# WKUP_ECC_AGGR0_ECC_AGGR register map
Vendor: Texas Instruments
Peripheral module from a debugger description file (folder am65x).
Registers are 32-bit, access not given, reset 0x0 unless marked. A register's access mark holds for its fields unless they carry their own. Offsets are as the file gives them; lines under a group give offsets from that group; [hi:lo] are bit positions; {n}, {i} and the like mark numbered series; 'fields as' and 'values as' point back to an identical list; <NAME> marks a mode.

## WKUP_ECC_AGGR0_ECC_AGGR
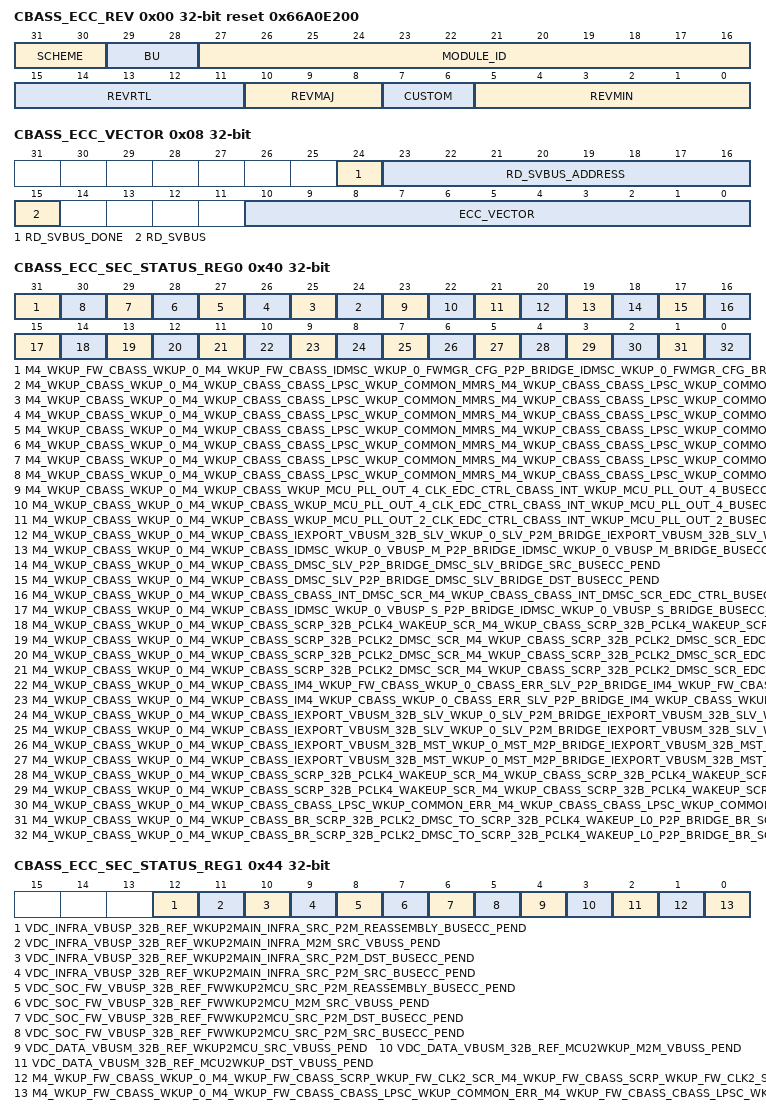
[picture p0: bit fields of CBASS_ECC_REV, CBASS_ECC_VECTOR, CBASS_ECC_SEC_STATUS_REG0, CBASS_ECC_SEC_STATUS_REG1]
0x00 CBASS_ECC_REV ro reset 0x66A0E200 — Return to the . Revision parameters
  [31:30] SCHEME
  [29:28] BU
  [27:16] MODULE_ID
  [15:11] REVRTL — RTL version
  [10:8] REVMAJ — Major version
  [7:6] CUSTOM — Custom version
  [5:0] REVMIN — Minor version
0x08 CBASS_ECC_VECTOR — Return to the . ECC Vector Register
  [24] RD_SVBUS_DONE — Status to indicate if read on serial VBUS is complete, write of any value will clear this bit. (access RW1C)
  [23:16] RD_SVBUS_ADDRESS rw — Read address
  [15] RD_SVBUS — Write 1 to trigger a read on the serial VBUS (access RW1S)
  [10:0] ECC_VECTOR rw — Value written to select the corresponding ECC RAM for control or status
0x0C CBASS_ECC_STAT ro reset 0x2D — Return to the . Misc Status
  [10:0] NUM_RAMS — Indicates the number of RAMS serviced by the ECC aggregator
0x3C CBASS_ECC_SEC_EOI_REG — Return to the . EOI Register
  [0] EOI_WR — EOI Register (access RW1S)
0x40 CBASS_ECC_SEC_STATUS_REG0 — Return to the . Interrupt Status Register 0
  [31] M4_WKUP_FW_CBASS_WKUP_0_M4_WKUP_FW_CBASS_IDMSC_WKUP_0_FWMGR_CFG_P2P_BRIDGE_IDMSC_WKUP_0_FWMGR_CFG_BRIDGE_BUSECC_PEND — Interrupt Pending Status for m4_wkup_fw_cbass_wkup_0_m4_wkup_fw_cbass_Idmsc_wkup_0_fwmgr_cfg_p2p_bridge_Idmsc_wkup_0_fwmgr_cfg_bridge_busecc__pend (access RW1S)
  [n+24] M4_WKUP_CBASS_WKUP_0_M4_WKUP_CBASS_CBASS_LPSC_WKUP_COMMON_MMRS_M4_WKUP_CBASS_CBASS_LPSC_WKUP_COMMON_MMRS_EDC_CTRL_BUSECC_{n}_PEND (n=0..6) — Interrupt Pending Status for m4_wkup_cbass_wkup_0_m4_wkup_cbass_cbass_LPSC_wkup_common_mmrs_m4_wkup_cbass_cbass_LPSC_wkup_common_mmrs_edc_ctrl_busecc_{n}__pend (access RW1S)
  [23] M4_WKUP_CBASS_WKUP_0_M4_WKUP_CBASS_WKUP_MCU_PLL_OUT_4_CLK_EDC_CTRL_CBASS_INT_WKUP_MCU_PLL_OUT_4_BUSECC_1_PEND — Interrupt Pending Status for m4_wkup_cbass_wkup_0_m4_wkup_cbass_wkup_mcu_pll_out_4_clk_edc_ctrl_cbass_int_wkup_mcu_pll_out_4_busecc_1__pend (access RW1S)
  [22] M4_WKUP_CBASS_WKUP_0_M4_WKUP_CBASS_WKUP_MCU_PLL_OUT_4_CLK_EDC_CTRL_CBASS_INT_WKUP_MCU_PLL_OUT_4_BUSECC_0_PEND — Interrupt Pending Status for m4_wkup_cbass_wkup_0_m4_wkup_cbass_wkup_mcu_pll_out_4_clk_edc_ctrl_cbass_int_wkup_mcu_pll_out_4_busecc_0__pend (access RW1S)
  [21] M4_WKUP_CBASS_WKUP_0_M4_WKUP_CBASS_WKUP_MCU_PLL_OUT_2_CLK_EDC_CTRL_CBASS_INT_WKUP_MCU_PLL_OUT_2_BUSECC_PEND — Interrupt Pending Status for m4_wkup_cbass_wkup_0_m4_wkup_cbass_wkup_mcu_pll_out_2_clk_edc_ctrl_cbass_int_wkup_mcu_pll_out_2_busecc__pend (access RW1S)
  [20] M4_WKUP_CBASS_WKUP_0_M4_WKUP_CBASS_IEXPORT_VBUSM_32B_SLV_WKUP_0_SLV_P2M_BRIDGE_IEXPORT_VBUSM_32B_SLV_WKUP_0_SLV_BRIDGE_REASSEMBLY_BUSECC_PEND — Interrupt Pending Status for m4_wkup_cbass_wkup_0_m4_wkup_cbass_Iexport_vbusm_32b_slv_wkup_0_slv_p2m_bridge_Iexport_vbusm_32b_slv_wkup_0_slv_bridge_reassembly_busecc__pend (access RW1S)
  [19] M4_WKUP_CBASS_WKUP_0_M4_WKUP_CBASS_IDMSC_WKUP_0_VBUSP_M_P2P_BRIDGE_IDMSC_WKUP_0_VBUSP_M_BRIDGE_BUSECC_PEND — Interrupt Pending Status for m4_wkup_cbass_wkup_0_m4_wkup_cbass_Idmsc_wkup_0_vbusp_m_p2p_bridge_Idmsc_wkup_0_vbusp_m_bridge_busecc__pend (access RW1S)
  [18] M4_WKUP_CBASS_WKUP_0_M4_WKUP_CBASS_DMSC_SLV_P2P_BRIDGE_DMSC_SLV_BRIDGE_SRC_BUSECC_PEND — Interrupt Pending Status for m4_wkup_cbass_wkup_0_m4_wkup_cbass_dmsc_slv_p2p_bridge_dmsc_slv_bridge_src_busecc__pend (access RW1S)
  [17] M4_WKUP_CBASS_WKUP_0_M4_WKUP_CBASS_DMSC_SLV_P2P_BRIDGE_DMSC_SLV_BRIDGE_DST_BUSECC_PEND — Interrupt Pending Status for m4_wkup_cbass_wkup_0_m4_wkup_cbass_dmsc_slv_p2p_bridge_dmsc_slv_bridge_dst_busecc__pend (access RW1S)
  [16] M4_WKUP_CBASS_WKUP_0_M4_WKUP_CBASS_CBASS_INT_DMSC_SCR_M4_WKUP_CBASS_CBASS_INT_DMSC_SCR_EDC_CTRL_BUSECC_PEND — Interrupt Pending Status for m4_wkup_cbass_wkup_0_m4_wkup_cbass_cbass_int_dmsc_scr_m4_wkup_cbass_cbass_int_dmsc_scr_edc_ctrl_busecc__pend (access RW1S)
  [15] M4_WKUP_CBASS_WKUP_0_M4_WKUP_CBASS_IDMSC_WKUP_0_VBUSP_S_P2P_BRIDGE_IDMSC_WKUP_0_VBUSP_S_BRIDGE_BUSECC_PEND — Interrupt Pending Status for m4_wkup_cbass_wkup_0_m4_wkup_cbass_Idmsc_wkup_0_vbusp_s_p2p_bridge_Idmsc_wkup_0_vbusp_s_bridge_busecc__pend (access RW1S)
  [14] M4_WKUP_CBASS_WKUP_0_M4_WKUP_CBASS_SCRP_32B_PCLK4_WAKEUP_SCR_M4_WKUP_CBASS_SCRP_32B_PCLK4_WAKEUP_SCR_EDC_CTRL_BUSECC_2_PEND — Interrupt Pending Status for m4_wkup_cbass_wkup_0_m4_wkup_cbass_SCRP_32b_PCLK4_wakeup_scr_m4_wkup_cbass_SCRP_32b_PCLK4_wakeup_scr_edc_ctrl_busecc_2__pend (access RW1S)
  [13] M4_WKUP_CBASS_WKUP_0_M4_WKUP_CBASS_SCRP_32B_PCLK2_DMSC_SCR_M4_WKUP_CBASS_SCRP_32B_PCLK2_DMSC_SCR_EDC_CTRL_BUSECC_2_PEND — Interrupt Pending Status for m4_wkup_cbass_wkup_0_m4_wkup_cbass_SCRP_32b_PCLK2_DMSC_scr_m4_wkup_cbass_SCRP_32b_PCLK2_DMSC_scr_edc_ctrl_busecc_2__pend (access RW1S)
  [12] M4_WKUP_CBASS_WKUP_0_M4_WKUP_CBASS_SCRP_32B_PCLK2_DMSC_SCR_M4_WKUP_CBASS_SCRP_32B_PCLK2_DMSC_SCR_EDC_CTRL_BUSECC_1_PEND — Interrupt Pending Status for m4_wkup_cbass_wkup_0_m4_wkup_cbass_SCRP_32b_PCLK2_DMSC_scr_m4_wkup_cbass_SCRP_32b_PCLK2_DMSC_scr_edc_ctrl_busecc_1__pend (access RW1S)
  [11] M4_WKUP_CBASS_WKUP_0_M4_WKUP_CBASS_SCRP_32B_PCLK2_DMSC_SCR_M4_WKUP_CBASS_SCRP_32B_PCLK2_DMSC_SCR_EDC_CTRL_BUSECC_0_PEND — Interrupt Pending Status for m4_wkup_cbass_wkup_0_m4_wkup_cbass_SCRP_32b_PCLK2_DMSC_scr_m4_wkup_cbass_SCRP_32b_PCLK2_DMSC_scr_edc_ctrl_busecc_0__pend (access RW1S)
  [10] M4_WKUP_CBASS_WKUP_0_M4_WKUP_CBASS_IM4_WKUP_FW_CBASS_WKUP_0_CBASS_ERR_SLV_P2P_BRIDGE_IM4_WKUP_FW_CBASS_WKUP_0_CBASS_ERR_SLV_BRIDGE_BUSECC_PEND — Interrupt Pending Status for m4_wkup_cbass_wkup_0_m4_wkup_cbass_Im4_wkup_fw_cbass_wkup_0_cbass_err_slv_p2p_bridge_Im4_wkup_fw_cbass_wkup_0_cbass_err_slv_bridge_busecc__pend (access RW1S)
  [9] M4_WKUP_CBASS_WKUP_0_M4_WKUP_CBASS_IM4_WKUP_CBASS_WKUP_0_CBASS_ERR_SLV_P2P_BRIDGE_IM4_WKUP_CBASS_WKUP_0_CBASS_ERR_SLV_BRIDGE_BUSECC_PEND — Interrupt Pending Status for m4_wkup_cbass_wkup_0_m4_wkup_cbass_Im4_wkup_cbass_wkup_0_cbass_err_slv_p2p_bridge_Im4_wkup_cbass_wkup_0_cbass_err_slv_bridge_busecc__pend (access RW1S)
  [8] M4_WKUP_CBASS_WKUP_0_M4_WKUP_CBASS_IEXPORT_VBUSM_32B_SLV_WKUP_0_SLV_P2M_BRIDGE_IEXPORT_VBUSM_32B_SLV_WKUP_0_SLV_BRIDGE_SRC_BUSECC_PEND — Interrupt Pending Status for m4_wkup_cbass_wkup_0_m4_wkup_cbass_Iexport_vbusm_32b_slv_wkup_0_slv_p2m_bridge_Iexport_vbusm_32b_slv_wkup_0_slv_bridge_src_busecc__pend (access RW1S)
  [7] M4_WKUP_CBASS_WKUP_0_M4_WKUP_CBASS_IEXPORT_VBUSM_32B_SLV_WKUP_0_SLV_P2M_BRIDGE_IEXPORT_VBUSM_32B_SLV_WKUP_0_SLV_BRIDGE_DST_BUSECC_PEND — Interrupt Pending Status for m4_wkup_cbass_wkup_0_m4_wkup_cbass_Iexport_vbusm_32b_slv_wkup_0_slv_p2m_bridge_Iexport_vbusm_32b_slv_wkup_0_slv_bridge_dst_busecc__pend (access RW1S)
  [6] M4_WKUP_CBASS_WKUP_0_M4_WKUP_CBASS_IEXPORT_VBUSM_32B_MST_WKUP_0_MST_M2P_BRIDGE_IEXPORT_VBUSM_32B_MST_WKUP_0_MST_BRIDGE_SRC_BUSECC_PEND — Interrupt Pending Status for m4_wkup_cbass_wkup_0_m4_wkup_cbass_Iexport_vbusm_32b_mst_wkup_0_mst_m2p_bridge_Iexport_vbusm_32b_mst_wkup_0_mst_bridge_src_busecc__pend (access RW1S)
  [5] M4_WKUP_CBASS_WKUP_0_M4_WKUP_CBASS_IEXPORT_VBUSM_32B_MST_WKUP_0_MST_M2P_BRIDGE_IEXPORT_VBUSM_32B_MST_WKUP_0_MST_BRIDGE_DST_BUSECC_PEND — Interrupt Pending Status for m4_wkup_cbass_wkup_0_m4_wkup_cbass_Iexport_vbusm_32b_mst_wkup_0_mst_m2p_bridge_Iexport_vbusm_32b_mst_wkup_0_mst_bridge_dst_busecc__pend (access RW1S)
  [4] M4_WKUP_CBASS_WKUP_0_M4_WKUP_CBASS_SCRP_32B_PCLK4_WAKEUP_SCR_M4_WKUP_CBASS_SCRP_32B_PCLK4_WAKEUP_SCR_EDC_CTRL_BUSECC_1_PEND — Interrupt Pending Status for m4_wkup_cbass_wkup_0_m4_wkup_cbass_SCRP_32b_PCLK4_wakeup_scr_m4_wkup_cbass_SCRP_32b_PCLK4_wakeup_scr_edc_ctrl_busecc_1__pend (access RW1S)
  [3] M4_WKUP_CBASS_WKUP_0_M4_WKUP_CBASS_SCRP_32B_PCLK4_WAKEUP_SCR_M4_WKUP_CBASS_SCRP_32B_PCLK4_WAKEUP_SCR_EDC_CTRL_BUSECC_0_PEND — Interrupt Pending Status for m4_wkup_cbass_wkup_0_m4_wkup_cbass_SCRP_32b_PCLK4_wakeup_scr_m4_wkup_cbass_SCRP_32b_PCLK4_wakeup_scr_edc_ctrl_busecc_0__pend (access RW1S)
  [2] M4_WKUP_CBASS_WKUP_0_M4_WKUP_CBASS_CBASS_LPSC_WKUP_COMMON_ERR_M4_WKUP_CBASS_CBASS_LPSC_WKUP_COMMON_ERR_EDC_CTRL_BUSECC_PEND — Interrupt Pending Status for m4_wkup_cbass_wkup_0_m4_wkup_cbass_cbass_LPSC_wkup_common_err_m4_wkup_cbass_cbass_LPSC_wkup_common_err_edc_ctrl_busecc__pend (access RW1S)
  [1] M4_WKUP_CBASS_WKUP_0_M4_WKUP_CBASS_BR_SCRP_32B_PCLK2_DMSC_TO_SCRP_32B_PCLK4_WAKEUP_L0_P2P_BRIDGE_BR_SCRP_32B_PCLK2_DMSC_TO_SCRP_32B_PCLK4_WAKEUP_L0_BRIDGE_SRC_BUSECC_PEND — Interrupt Pending Status for m4_wkup_cbass_wkup_0_m4_wkup_cbass_br_SCRP_32b_PCLK2_DMSC_to_SCRP_32b_PCLK4_wakeup_l0_p2p_bridge_br_SCRP_32b_PCLK2_DMSC_to_SCRP_32b_PCLK4_wakeup_l0_bridge_src_busecc__pend (access RW1S)
  [0] M4_WKUP_CBASS_WKUP_0_M4_WKUP_CBASS_BR_SCRP_32B_PCLK2_DMSC_TO_SCRP_32B_PCLK4_WAKEUP_L0_P2P_BRIDGE_BR_SCRP_32B_PCLK2_DMSC_TO_SCRP_32B_PCLK4_WAKEUP_L0_BRIDGE_DST_BUSECC_PEND — Interrupt Pending Status for m4_wkup_cbass_wkup_0_m4_wkup_cbass_br_SCRP_32b_PCLK2_DMSC_to_SCRP_32b_PCLK4_wakeup_l0_p2p_bridge_br_SCRP_32b_PCLK2_DMSC_to_SCRP_32b_PCLK4_wakeup_l0_bridge_dst_busecc__pend (access RW1S)
0x44 CBASS_ECC_SEC_STATUS_REG1 — Return to the . Interrupt Status Register 1
  [12] VDC_INFRA_VBUSP_32B_REF_WKUP2MAIN_INFRA_SRC_P2M_REASSEMBLY_BUSECC_PEND — Interrupt Pending Status for vdc_infra_vbusp_32b_ref_wkup2main_infra_src_p2m_reassembly_busecc__pend (access RW1S)
  [11] VDC_INFRA_VBUSP_32B_REF_WKUP2MAIN_INFRA_M2M_SRC_VBUSS_PEND — Interrupt Pending Status for vdc_infra_vbusp_32b_ref_wkup2main_infra_m2m_src_vbuss__pend (access RW1S)
  [10] VDC_INFRA_VBUSP_32B_REF_WKUP2MAIN_INFRA_SRC_P2M_DST_BUSECC_PEND — Interrupt Pending Status for vdc_infra_vbusp_32b_ref_wkup2main_infra_src_p2m_dst_busecc__pend (access RW1S)
  [9] VDC_INFRA_VBUSP_32B_REF_WKUP2MAIN_INFRA_SRC_P2M_SRC_BUSECC_PEND — Interrupt Pending Status for vdc_infra_vbusp_32b_ref_wkup2main_infra_src_p2m_src_busecc__pend (access RW1S)
  [8] VDC_SOC_FW_VBUSP_32B_REF_FWWKUP2MCU_SRC_P2M_REASSEMBLY_BUSECC_PEND — Interrupt Pending Status for vdc_soc_fw_vbusp_32b_ref_fwwkup2mcu_src_p2m_reassembly_busecc__pend (access RW1S)
  [7] VDC_SOC_FW_VBUSP_32B_REF_FWWKUP2MCU_M2M_SRC_VBUSS_PEND — Interrupt Pending Status for vdc_soc_fw_vbusp_32b_ref_fwwkup2mcu_m2m_src_vbuss__pend (access RW1S)
  [6] VDC_SOC_FW_VBUSP_32B_REF_FWWKUP2MCU_SRC_P2M_DST_BUSECC_PEND — Interrupt Pending Status for vdc_soc_fw_vbusp_32b_ref_fwwkup2mcu_src_p2m_dst_busecc__pend (access RW1S)
  [5] VDC_SOC_FW_VBUSP_32B_REF_FWWKUP2MCU_SRC_P2M_SRC_BUSECC_PEND — Interrupt Pending Status for vdc_soc_fw_vbusp_32b_ref_fwwkup2mcu_src_p2m_src_busecc__pend (access RW1S)
  [4] VDC_DATA_VBUSM_32B_REF_WKUP2MCU_SRC_VBUSS_PEND — Interrupt Pending Status for vdc_data_vbusm_32b_ref_wkup2mcu_src_vbuss__pend (access RW1S)
  [3] VDC_DATA_VBUSM_32B_REF_MCU2WKUP_M2M_VBUSS_PEND — Interrupt Pending Status for vdc_data_vbusm_32b_ref_mcu2wkup_m2m_vbuss__pend (access RW1S)
  [2] VDC_DATA_VBUSM_32B_REF_MCU2WKUP_DST_VBUSS_PEND — Interrupt Pending Status for vdc_data_vbusm_32b_ref_mcu2wkup_dst_vbuss__pend (access RW1S)
  [1] M4_WKUP_FW_CBASS_WKUP_0_M4_WKUP_FW_CBASS_SCRP_WKUP_FW_CLK2_SCR_M4_WKUP_FW_CBASS_SCRP_WKUP_FW_CLK2_SCR_EDC_CTRL_BUSECC_PEND — Interrupt Pending Status for m4_wkup_fw_cbass_wkup_0_m4_wkup_fw_cbass_SCRP_wkup_fw_CLK2_scr_m4_wkup_fw_cbass_SCRP_wkup_fw_CLK2_scr_edc_ctrl_busecc__pend (access RW1S)
  [0] M4_WKUP_FW_CBASS_WKUP_0_M4_WKUP_FW_CBASS_CBASS_LPSC_WKUP_COMMON_ERR_M4_WKUP_FW_CBASS_CBASS_LPSC_WKUP_COMMON_ERR_EDC_CTRL_BUSECC_PEND — Interrupt Pending Status for m4_wkup_fw_cbass_wkup_0_m4_wkup_fw_cbass_cbass_LPSC_wkup_common_err_m4_wkup_fw_cbass_cbass_LPSC_wkup_common_err_edc_ctrl_busecc__pend (access RW1S)
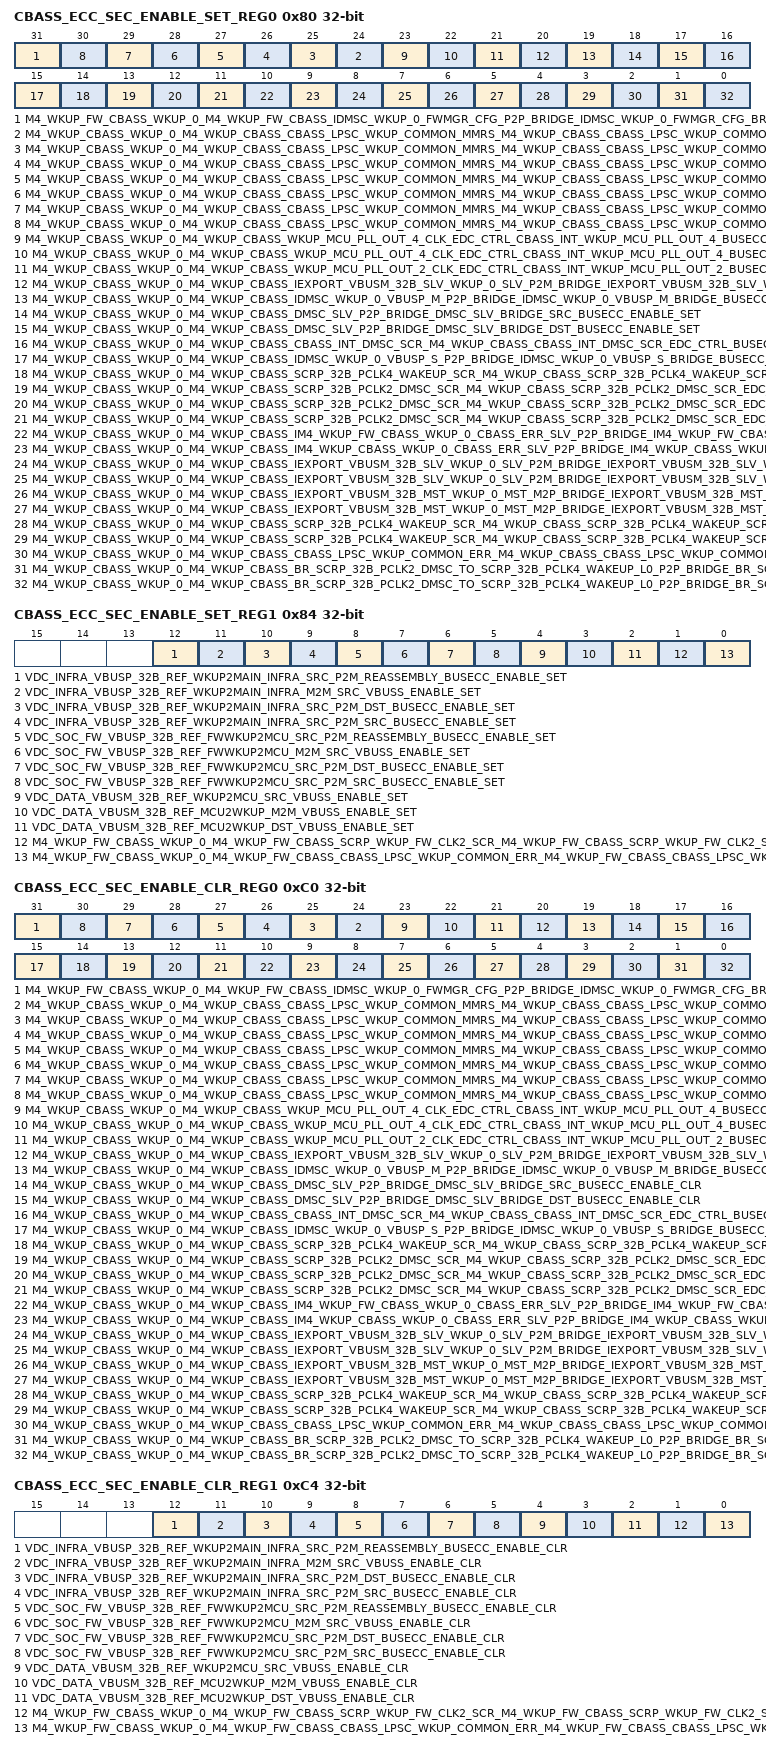
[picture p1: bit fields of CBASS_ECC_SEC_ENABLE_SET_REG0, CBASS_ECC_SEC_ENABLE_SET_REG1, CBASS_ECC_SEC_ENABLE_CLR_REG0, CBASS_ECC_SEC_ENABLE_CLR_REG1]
0x80 CBASS_ECC_SEC_ENABLE_SET_REG0 — Return to the . Interrupt Enable Set Register 0
  [31] M4_WKUP_FW_CBASS_WKUP_0_M4_WKUP_FW_CBASS_IDMSC_WKUP_0_FWMGR_CFG_P2P_BRIDGE_IDMSC_WKUP_0_FWMGR_CFG_BRIDGE_BUSECC_ENABLE_SET — Interrupt Enable Set Register for m4_wkup_fw_cbass_wkup_0_m4_wkup_fw_cbass_Idmsc_wkup_0_fwmgr_cfg_p2p_bridge_Idmsc_wkup_0_fwmgr_cfg_bridge_busecc__pend (access RW1S)
  [n+24] M4_WKUP_CBASS_WKUP_0_M4_WKUP_CBASS_CBASS_LPSC_WKUP_COMMON_MMRS_M4_WKUP_CBASS_CBASS_LPSC_WKUP_COMMON_MMRS_EDC_CTRL_BUSECC_{n}_ENABLE_SET (n=0..6) — Interrupt Enable Set Register for m4_wkup_cbass_wkup_0_m4_wkup_cbass_cbass_LPSC_wkup_common_mmrs_m4_wkup_cbass_cbass_LPSC_wkup_common_mmrs_edc_ctrl_busecc_{n}__pend (access RW1S)
  [23] M4_WKUP_CBASS_WKUP_0_M4_WKUP_CBASS_WKUP_MCU_PLL_OUT_4_CLK_EDC_CTRL_CBASS_INT_WKUP_MCU_PLL_OUT_4_BUSECC_1_ENABLE_SET — Interrupt Enable Set Register for m4_wkup_cbass_wkup_0_m4_wkup_cbass_wkup_mcu_pll_out_4_clk_edc_ctrl_cbass_int_wkup_mcu_pll_out_4_busecc_1__pend (access RW1S)
  [22] M4_WKUP_CBASS_WKUP_0_M4_WKUP_CBASS_WKUP_MCU_PLL_OUT_4_CLK_EDC_CTRL_CBASS_INT_WKUP_MCU_PLL_OUT_4_BUSECC_0_ENABLE_SET — Interrupt Enable Set Register for m4_wkup_cbass_wkup_0_m4_wkup_cbass_wkup_mcu_pll_out_4_clk_edc_ctrl_cbass_int_wkup_mcu_pll_out_4_busecc_0__pend (access RW1S)
  [21] M4_WKUP_CBASS_WKUP_0_M4_WKUP_CBASS_WKUP_MCU_PLL_OUT_2_CLK_EDC_CTRL_CBASS_INT_WKUP_MCU_PLL_OUT_2_BUSECC_ENABLE_SET — Interrupt Enable Set Register for m4_wkup_cbass_wkup_0_m4_wkup_cbass_wkup_mcu_pll_out_2_clk_edc_ctrl_cbass_int_wkup_mcu_pll_out_2_busecc__pend (access RW1S)
  [20] M4_WKUP_CBASS_WKUP_0_M4_WKUP_CBASS_IEXPORT_VBUSM_32B_SLV_WKUP_0_SLV_P2M_BRIDGE_IEXPORT_VBUSM_32B_SLV_WKUP_0_SLV_BRIDGE_REASSEMBLY_BUSECC_ENABLE_SET — Interrupt Enable Set Register for m4_wkup_cbass_wkup_0_m4_wkup_cbass_Iexport_vbusm_32b_slv_wkup_0_slv_p2m_bridge_Iexport_vbusm_32b_slv_wkup_0_slv_bridge_reassembly_busecc__pend (access RW1S)
  [19] M4_WKUP_CBASS_WKUP_0_M4_WKUP_CBASS_IDMSC_WKUP_0_VBUSP_M_P2P_BRIDGE_IDMSC_WKUP_0_VBUSP_M_BRIDGE_BUSECC_ENABLE_SET — Interrupt Enable Set Register for m4_wkup_cbass_wkup_0_m4_wkup_cbass_Idmsc_wkup_0_vbusp_m_p2p_bridge_Idmsc_wkup_0_vbusp_m_bridge_busecc__pend (access RW1S)
  [18] M4_WKUP_CBASS_WKUP_0_M4_WKUP_CBASS_DMSC_SLV_P2P_BRIDGE_DMSC_SLV_BRIDGE_SRC_BUSECC_ENABLE_SET — Interrupt Enable Set Register for m4_wkup_cbass_wkup_0_m4_wkup_cbass_dmsc_slv_p2p_bridge_dmsc_slv_bridge_src_busecc__pend (access RW1S)
  [17] M4_WKUP_CBASS_WKUP_0_M4_WKUP_CBASS_DMSC_SLV_P2P_BRIDGE_DMSC_SLV_BRIDGE_DST_BUSECC_ENABLE_SET — Interrupt Enable Set Register for m4_wkup_cbass_wkup_0_m4_wkup_cbass_dmsc_slv_p2p_bridge_dmsc_slv_bridge_dst_busecc__pend (access RW1S)
  [16] M4_WKUP_CBASS_WKUP_0_M4_WKUP_CBASS_CBASS_INT_DMSC_SCR_M4_WKUP_CBASS_CBASS_INT_DMSC_SCR_EDC_CTRL_BUSECC_ENABLE_SET — Interrupt Enable Set Register for m4_wkup_cbass_wkup_0_m4_wkup_cbass_cbass_int_dmsc_scr_m4_wkup_cbass_cbass_int_dmsc_scr_edc_ctrl_busecc__pend (access RW1S)
  [15] M4_WKUP_CBASS_WKUP_0_M4_WKUP_CBASS_IDMSC_WKUP_0_VBUSP_S_P2P_BRIDGE_IDMSC_WKUP_0_VBUSP_S_BRIDGE_BUSECC_ENABLE_SET — Interrupt Enable Set Register for m4_wkup_cbass_wkup_0_m4_wkup_cbass_Idmsc_wkup_0_vbusp_s_p2p_bridge_Idmsc_wkup_0_vbusp_s_bridge_busecc__pend (access RW1S)
  [14] M4_WKUP_CBASS_WKUP_0_M4_WKUP_CBASS_SCRP_32B_PCLK4_WAKEUP_SCR_M4_WKUP_CBASS_SCRP_32B_PCLK4_WAKEUP_SCR_EDC_CTRL_BUSECC_2_ENABLE_SET — Interrupt Enable Set Register for m4_wkup_cbass_wkup_0_m4_wkup_cbass_SCRP_32b_PCLK4_wakeup_scr_m4_wkup_cbass_SCRP_32b_PCLK4_wakeup_scr_edc_ctrl_busecc_2__pend (access RW1S)
  [13] M4_WKUP_CBASS_WKUP_0_M4_WKUP_CBASS_SCRP_32B_PCLK2_DMSC_SCR_M4_WKUP_CBASS_SCRP_32B_PCLK2_DMSC_SCR_EDC_CTRL_BUSECC_2_ENABLE_SET — Interrupt Enable Set Register for m4_wkup_cbass_wkup_0_m4_wkup_cbass_SCRP_32b_PCLK2_DMSC_scr_m4_wkup_cbass_SCRP_32b_PCLK2_DMSC_scr_edc_ctrl_busecc_2__pend (access RW1S)
  [12] M4_WKUP_CBASS_WKUP_0_M4_WKUP_CBASS_SCRP_32B_PCLK2_DMSC_SCR_M4_WKUP_CBASS_SCRP_32B_PCLK2_DMSC_SCR_EDC_CTRL_BUSECC_1_ENABLE_SET — Interrupt Enable Set Register for m4_wkup_cbass_wkup_0_m4_wkup_cbass_SCRP_32b_PCLK2_DMSC_scr_m4_wkup_cbass_SCRP_32b_PCLK2_DMSC_scr_edc_ctrl_busecc_1__pend (access RW1S)
  [11] M4_WKUP_CBASS_WKUP_0_M4_WKUP_CBASS_SCRP_32B_PCLK2_DMSC_SCR_M4_WKUP_CBASS_SCRP_32B_PCLK2_DMSC_SCR_EDC_CTRL_BUSECC_0_ENABLE_SET — Interrupt Enable Set Register for m4_wkup_cbass_wkup_0_m4_wkup_cbass_SCRP_32b_PCLK2_DMSC_scr_m4_wkup_cbass_SCRP_32b_PCLK2_DMSC_scr_edc_ctrl_busecc_0__pend (access RW1S)
  [10] M4_WKUP_CBASS_WKUP_0_M4_WKUP_CBASS_IM4_WKUP_FW_CBASS_WKUP_0_CBASS_ERR_SLV_P2P_BRIDGE_IM4_WKUP_FW_CBASS_WKUP_0_CBASS_ERR_SLV_BRIDGE_BUSECC_ENABLE_SET — Interrupt Enable Set Register for m4_wkup_cbass_wkup_0_m4_wkup_cbass_Im4_wkup_fw_cbass_wkup_0_cbass_err_slv_p2p_bridge_Im4_wkup_fw_cbass_wkup_0_cbass_err_slv_bridge_busecc__pend (access RW1S)
  [9] M4_WKUP_CBASS_WKUP_0_M4_WKUP_CBASS_IM4_WKUP_CBASS_WKUP_0_CBASS_ERR_SLV_P2P_BRIDGE_IM4_WKUP_CBASS_WKUP_0_CBASS_ERR_SLV_BRIDGE_BUSECC_ENABLE_SET — Interrupt Enable Set Register for m4_wkup_cbass_wkup_0_m4_wkup_cbass_Im4_wkup_cbass_wkup_0_cbass_err_slv_p2p_bridge_Im4_wkup_cbass_wkup_0_cbass_err_slv_bridge_busecc__pend (access RW1S)
  [8] M4_WKUP_CBASS_WKUP_0_M4_WKUP_CBASS_IEXPORT_VBUSM_32B_SLV_WKUP_0_SLV_P2M_BRIDGE_IEXPORT_VBUSM_32B_SLV_WKUP_0_SLV_BRIDGE_SRC_BUSECC_ENABLE_SET — Interrupt Enable Set Register for m4_wkup_cbass_wkup_0_m4_wkup_cbass_Iexport_vbusm_32b_slv_wkup_0_slv_p2m_bridge_Iexport_vbusm_32b_slv_wkup_0_slv_bridge_src_busecc__pend (access RW1S)
  [7] M4_WKUP_CBASS_WKUP_0_M4_WKUP_CBASS_IEXPORT_VBUSM_32B_SLV_WKUP_0_SLV_P2M_BRIDGE_IEXPORT_VBUSM_32B_SLV_WKUP_0_SLV_BRIDGE_DST_BUSECC_ENABLE_SET — Interrupt Enable Set Register for m4_wkup_cbass_wkup_0_m4_wkup_cbass_Iexport_vbusm_32b_slv_wkup_0_slv_p2m_bridge_Iexport_vbusm_32b_slv_wkup_0_slv_bridge_dst_busecc__pend (access RW1S)
  [6] M4_WKUP_CBASS_WKUP_0_M4_WKUP_CBASS_IEXPORT_VBUSM_32B_MST_WKUP_0_MST_M2P_BRIDGE_IEXPORT_VBUSM_32B_MST_WKUP_0_MST_BRIDGE_SRC_BUSECC_ENABLE_SET — Interrupt Enable Set Register for m4_wkup_cbass_wkup_0_m4_wkup_cbass_Iexport_vbusm_32b_mst_wkup_0_mst_m2p_bridge_Iexport_vbusm_32b_mst_wkup_0_mst_bridge_src_busecc__pend (access RW1S)
  [5] M4_WKUP_CBASS_WKUP_0_M4_WKUP_CBASS_IEXPORT_VBUSM_32B_MST_WKUP_0_MST_M2P_BRIDGE_IEXPORT_VBUSM_32B_MST_WKUP_0_MST_BRIDGE_DST_BUSECC_ENABLE_SET — Interrupt Enable Set Register for m4_wkup_cbass_wkup_0_m4_wkup_cbass_Iexport_vbusm_32b_mst_wkup_0_mst_m2p_bridge_Iexport_vbusm_32b_mst_wkup_0_mst_bridge_dst_busecc__pend (access RW1S)
  [4] M4_WKUP_CBASS_WKUP_0_M4_WKUP_CBASS_SCRP_32B_PCLK4_WAKEUP_SCR_M4_WKUP_CBASS_SCRP_32B_PCLK4_WAKEUP_SCR_EDC_CTRL_BUSECC_1_ENABLE_SET — Interrupt Enable Set Register for m4_wkup_cbass_wkup_0_m4_wkup_cbass_SCRP_32b_PCLK4_wakeup_scr_m4_wkup_cbass_SCRP_32b_PCLK4_wakeup_scr_edc_ctrl_busecc_1__pend (access RW1S)
  [3] M4_WKUP_CBASS_WKUP_0_M4_WKUP_CBASS_SCRP_32B_PCLK4_WAKEUP_SCR_M4_WKUP_CBASS_SCRP_32B_PCLK4_WAKEUP_SCR_EDC_CTRL_BUSECC_0_ENABLE_SET — Interrupt Enable Set Register for m4_wkup_cbass_wkup_0_m4_wkup_cbass_SCRP_32b_PCLK4_wakeup_scr_m4_wkup_cbass_SCRP_32b_PCLK4_wakeup_scr_edc_ctrl_busecc_0__pend (access RW1S)
  [2] M4_WKUP_CBASS_WKUP_0_M4_WKUP_CBASS_CBASS_LPSC_WKUP_COMMON_ERR_M4_WKUP_CBASS_CBASS_LPSC_WKUP_COMMON_ERR_EDC_CTRL_BUSECC_ENABLE_SET — Interrupt Enable Set Register for m4_wkup_cbass_wkup_0_m4_wkup_cbass_cbass_LPSC_wkup_common_err_m4_wkup_cbass_cbass_LPSC_wkup_common_err_edc_ctrl_busecc__pend (access RW1S)
  [1] M4_WKUP_CBASS_WKUP_0_M4_WKUP_CBASS_BR_SCRP_32B_PCLK2_DMSC_TO_SCRP_32B_PCLK4_WAKEUP_L0_P2P_BRIDGE_BR_SCRP_32B_PCLK2_DMSC_TO_SCRP_32B_PCLK4_WAKEUP_L0_BRIDGE_SRC_BUSECC_ENABLE_SET — Interrupt Enable Set Register for m4_wkup_cbass_wkup_0_m4_wkup_cbass_br_SCRP_32b_PCLK2_DMSC_to_SCRP_32b_PCLK4_wakeup_l0_p2p_bridge_br_SCRP_32b_PCLK2_DMSC_to_SCRP_32b_PCLK4_wakeup_l0_bridge_src_busecc__pend (access RW1S)
  [0] M4_WKUP_CBASS_WKUP_0_M4_WKUP_CBASS_BR_SCRP_32B_PCLK2_DMSC_TO_SCRP_32B_PCLK4_WAKEUP_L0_P2P_BRIDGE_BR_SCRP_32B_PCLK2_DMSC_TO_SCRP_32B_PCLK4_WAKEUP_L0_BRIDGE_DST_BUSECC_ENABLE_SET — Interrupt Enable Set Register for m4_wkup_cbass_wkup_0_m4_wkup_cbass_br_SCRP_32b_PCLK2_DMSC_to_SCRP_32b_PCLK4_wakeup_l0_p2p_bridge_br_SCRP_32b_PCLK2_DMSC_to_SCRP_32b_PCLK4_wakeup_l0_bridge_dst_busecc__pend (access RW1S)
0x84 CBASS_ECC_SEC_ENABLE_SET_REG1 — Return to the . Interrupt Enable Set Register 1
  [12] VDC_INFRA_VBUSP_32B_REF_WKUP2MAIN_INFRA_SRC_P2M_REASSEMBLY_BUSECC_ENABLE_SET — Interrupt Enable Set Register for vdc_infra_vbusp_32b_ref_wkup2main_infra_src_p2m_reassembly_busecc__pend (access RW1S)
  [11] VDC_INFRA_VBUSP_32B_REF_WKUP2MAIN_INFRA_M2M_SRC_VBUSS_ENABLE_SET — Interrupt Enable Set Register for vdc_infra_vbusp_32b_ref_wkup2main_infra_m2m_src_vbuss__pend (access RW1S)
  [10] VDC_INFRA_VBUSP_32B_REF_WKUP2MAIN_INFRA_SRC_P2M_DST_BUSECC_ENABLE_SET — Interrupt Enable Set Register for vdc_infra_vbusp_32b_ref_wkup2main_infra_src_p2m_dst_busecc__pend (access RW1S)
  [9] VDC_INFRA_VBUSP_32B_REF_WKUP2MAIN_INFRA_SRC_P2M_SRC_BUSECC_ENABLE_SET — Interrupt Enable Set Register for vdc_infra_vbusp_32b_ref_wkup2main_infra_src_p2m_src_busecc__pend (access RW1S)
  [8] VDC_SOC_FW_VBUSP_32B_REF_FWWKUP2MCU_SRC_P2M_REASSEMBLY_BUSECC_ENABLE_SET — Interrupt Enable Set Register for vdc_soc_fw_vbusp_32b_ref_fwwkup2mcu_src_p2m_reassembly_busecc__pend (access RW1S)
  [7] VDC_SOC_FW_VBUSP_32B_REF_FWWKUP2MCU_M2M_SRC_VBUSS_ENABLE_SET — Interrupt Enable Set Register for vdc_soc_fw_vbusp_32b_ref_fwwkup2mcu_m2m_src_vbuss__pend (access RW1S)
  [6] VDC_SOC_FW_VBUSP_32B_REF_FWWKUP2MCU_SRC_P2M_DST_BUSECC_ENABLE_SET — Interrupt Enable Set Register for vdc_soc_fw_vbusp_32b_ref_fwwkup2mcu_src_p2m_dst_busecc__pend (access RW1S)
  [5] VDC_SOC_FW_VBUSP_32B_REF_FWWKUP2MCU_SRC_P2M_SRC_BUSECC_ENABLE_SET — Interrupt Enable Set Register for vdc_soc_fw_vbusp_32b_ref_fwwkup2mcu_src_p2m_src_busecc__pend (access RW1S)
  [4] VDC_DATA_VBUSM_32B_REF_WKUP2MCU_SRC_VBUSS_ENABLE_SET — Interrupt Enable Set Register for vdc_data_vbusm_32b_ref_wkup2mcu_src_vbuss__pend (access RW1S)
  [3] VDC_DATA_VBUSM_32B_REF_MCU2WKUP_M2M_VBUSS_ENABLE_SET — Interrupt Enable Set Register for vdc_data_vbusm_32b_ref_mcu2wkup_m2m_vbuss__pend (access RW1S)
  [2] VDC_DATA_VBUSM_32B_REF_MCU2WKUP_DST_VBUSS_ENABLE_SET — Interrupt Enable Set Register for vdc_data_vbusm_32b_ref_mcu2wkup_dst_vbuss__pend (access RW1S)
  [1] M4_WKUP_FW_CBASS_WKUP_0_M4_WKUP_FW_CBASS_SCRP_WKUP_FW_CLK2_SCR_M4_WKUP_FW_CBASS_SCRP_WKUP_FW_CLK2_SCR_EDC_CTRL_BUSECC_ENABLE_SET — Interrupt Enable Set Register for m4_wkup_fw_cbass_wkup_0_m4_wkup_fw_cbass_SCRP_wkup_fw_CLK2_scr_m4_wkup_fw_cbass_SCRP_wkup_fw_CLK2_scr_edc_ctrl_busecc__pend (access RW1S)
  [0] M4_WKUP_FW_CBASS_WKUP_0_M4_WKUP_FW_CBASS_CBASS_LPSC_WKUP_COMMON_ERR_M4_WKUP_FW_CBASS_CBASS_LPSC_WKUP_COMMON_ERR_EDC_CTRL_BUSECC_ENABLE_SET — Interrupt Enable Set Register for m4_wkup_fw_cbass_wkup_0_m4_wkup_fw_cbass_cbass_LPSC_wkup_common_err_m4_wkup_fw_cbass_cbass_LPSC_wkup_common_err_edc_ctrl_busecc__pend (access RW1S)
0xC0 CBASS_ECC_SEC_ENABLE_CLR_REG0 — Return to the . Interrupt Enable Clear Register 0
  [31] M4_WKUP_FW_CBASS_WKUP_0_M4_WKUP_FW_CBASS_IDMSC_WKUP_0_FWMGR_CFG_P2P_BRIDGE_IDMSC_WKUP_0_FWMGR_CFG_BRIDGE_BUSECC_ENABLE_CLR — Interrupt Enable Clear Register for m4_wkup_fw_cbass_wkup_0_m4_wkup_fw_cbass_Idmsc_wkup_0_fwmgr_cfg_p2p_bridge_Idmsc_wkup_0_fwmgr_cfg_bridge_busecc__pend (access RW1C)
  [n+24] M4_WKUP_CBASS_WKUP_0_M4_WKUP_CBASS_CBASS_LPSC_WKUP_COMMON_MMRS_M4_WKUP_CBASS_CBASS_LPSC_WKUP_COMMON_MMRS_EDC_CTRL_BUSECC_{n}_ENABLE_CLR (n=0..6) — Interrupt Enable Clear Register for m4_wkup_cbass_wkup_0_m4_wkup_cbass_cbass_LPSC_wkup_common_mmrs_m4_wkup_cbass_cbass_LPSC_wkup_common_mmrs_edc_ctrl_busecc_{n}__pend (access RW1C)
  [23] M4_WKUP_CBASS_WKUP_0_M4_WKUP_CBASS_WKUP_MCU_PLL_OUT_4_CLK_EDC_CTRL_CBASS_INT_WKUP_MCU_PLL_OUT_4_BUSECC_1_ENABLE_CLR — Interrupt Enable Clear Register for m4_wkup_cbass_wkup_0_m4_wkup_cbass_wkup_mcu_pll_out_4_clk_edc_ctrl_cbass_int_wkup_mcu_pll_out_4_busecc_1__pend (access RW1C)
  [22] M4_WKUP_CBASS_WKUP_0_M4_WKUP_CBASS_WKUP_MCU_PLL_OUT_4_CLK_EDC_CTRL_CBASS_INT_WKUP_MCU_PLL_OUT_4_BUSECC_0_ENABLE_CLR — Interrupt Enable Clear Register for m4_wkup_cbass_wkup_0_m4_wkup_cbass_wkup_mcu_pll_out_4_clk_edc_ctrl_cbass_int_wkup_mcu_pll_out_4_busecc_0__pend (access RW1C)
  [21] M4_WKUP_CBASS_WKUP_0_M4_WKUP_CBASS_WKUP_MCU_PLL_OUT_2_CLK_EDC_CTRL_CBASS_INT_WKUP_MCU_PLL_OUT_2_BUSECC_ENABLE_CLR — Interrupt Enable Clear Register for m4_wkup_cbass_wkup_0_m4_wkup_cbass_wkup_mcu_pll_out_2_clk_edc_ctrl_cbass_int_wkup_mcu_pll_out_2_busecc__pend (access RW1C)
  [20] M4_WKUP_CBASS_WKUP_0_M4_WKUP_CBASS_IEXPORT_VBUSM_32B_SLV_WKUP_0_SLV_P2M_BRIDGE_IEXPORT_VBUSM_32B_SLV_WKUP_0_SLV_BRIDGE_REASSEMBLY_BUSECC_ENABLE_CLR — Interrupt Enable Clear Register for m4_wkup_cbass_wkup_0_m4_wkup_cbass_Iexport_vbusm_32b_slv_wkup_0_slv_p2m_bridge_Iexport_vbusm_32b_slv_wkup_0_slv_bridge_reassembly_busecc__pend (access RW1C)
  [19] M4_WKUP_CBASS_WKUP_0_M4_WKUP_CBASS_IDMSC_WKUP_0_VBUSP_M_P2P_BRIDGE_IDMSC_WKUP_0_VBUSP_M_BRIDGE_BUSECC_ENABLE_CLR — Interrupt Enable Clear Register for m4_wkup_cbass_wkup_0_m4_wkup_cbass_Idmsc_wkup_0_vbusp_m_p2p_bridge_Idmsc_wkup_0_vbusp_m_bridge_busecc__pend (access RW1C)
  [18] M4_WKUP_CBASS_WKUP_0_M4_WKUP_CBASS_DMSC_SLV_P2P_BRIDGE_DMSC_SLV_BRIDGE_SRC_BUSECC_ENABLE_CLR — Interrupt Enable Clear Register for m4_wkup_cbass_wkup_0_m4_wkup_cbass_dmsc_slv_p2p_bridge_dmsc_slv_bridge_src_busecc__pend (access RW1C)
  [17] M4_WKUP_CBASS_WKUP_0_M4_WKUP_CBASS_DMSC_SLV_P2P_BRIDGE_DMSC_SLV_BRIDGE_DST_BUSECC_ENABLE_CLR — Interrupt Enable Clear Register for m4_wkup_cbass_wkup_0_m4_wkup_cbass_dmsc_slv_p2p_bridge_dmsc_slv_bridge_dst_busecc__pend (access RW1C)
  [16] M4_WKUP_CBASS_WKUP_0_M4_WKUP_CBASS_CBASS_INT_DMSC_SCR_M4_WKUP_CBASS_CBASS_INT_DMSC_SCR_EDC_CTRL_BUSECC_ENABLE_CLR — Interrupt Enable Clear Register for m4_wkup_cbass_wkup_0_m4_wkup_cbass_cbass_int_dmsc_scr_m4_wkup_cbass_cbass_int_dmsc_scr_edc_ctrl_busecc__pend (access RW1C)
  [15] M4_WKUP_CBASS_WKUP_0_M4_WKUP_CBASS_IDMSC_WKUP_0_VBUSP_S_P2P_BRIDGE_IDMSC_WKUP_0_VBUSP_S_BRIDGE_BUSECC_ENABLE_CLR — Interrupt Enable Clear Register for m4_wkup_cbass_wkup_0_m4_wkup_cbass_Idmsc_wkup_0_vbusp_s_p2p_bridge_Idmsc_wkup_0_vbusp_s_bridge_busecc__pend (access RW1C)
  [14] M4_WKUP_CBASS_WKUP_0_M4_WKUP_CBASS_SCRP_32B_PCLK4_WAKEUP_SCR_M4_WKUP_CBASS_SCRP_32B_PCLK4_WAKEUP_SCR_EDC_CTRL_BUSECC_2_ENABLE_CLR — Interrupt Enable Clear Register for m4_wkup_cbass_wkup_0_m4_wkup_cbass_SCRP_32b_PCLK4_wakeup_scr_m4_wkup_cbass_SCRP_32b_PCLK4_wakeup_scr_edc_ctrl_busecc_2__pend (access RW1C)
  [13] M4_WKUP_CBASS_WKUP_0_M4_WKUP_CBASS_SCRP_32B_PCLK2_DMSC_SCR_M4_WKUP_CBASS_SCRP_32B_PCLK2_DMSC_SCR_EDC_CTRL_BUSECC_2_ENABLE_CLR — Interrupt Enable Clear Register for m4_wkup_cbass_wkup_0_m4_wkup_cbass_SCRP_32b_PCLK2_DMSC_scr_m4_wkup_cbass_SCRP_32b_PCLK2_DMSC_scr_edc_ctrl_busecc_2__pend (access RW1C)
  [12] M4_WKUP_CBASS_WKUP_0_M4_WKUP_CBASS_SCRP_32B_PCLK2_DMSC_SCR_M4_WKUP_CBASS_SCRP_32B_PCLK2_DMSC_SCR_EDC_CTRL_BUSECC_1_ENABLE_CLR — Interrupt Enable Clear Register for m4_wkup_cbass_wkup_0_m4_wkup_cbass_SCRP_32b_PCLK2_DMSC_scr_m4_wkup_cbass_SCRP_32b_PCLK2_DMSC_scr_edc_ctrl_busecc_1__pend (access RW1C)
  [11] M4_WKUP_CBASS_WKUP_0_M4_WKUP_CBASS_SCRP_32B_PCLK2_DMSC_SCR_M4_WKUP_CBASS_SCRP_32B_PCLK2_DMSC_SCR_EDC_CTRL_BUSECC_0_ENABLE_CLR — Interrupt Enable Clear Register for m4_wkup_cbass_wkup_0_m4_wkup_cbass_SCRP_32b_PCLK2_DMSC_scr_m4_wkup_cbass_SCRP_32b_PCLK2_DMSC_scr_edc_ctrl_busecc_0__pend (access RW1C)
  [10] M4_WKUP_CBASS_WKUP_0_M4_WKUP_CBASS_IM4_WKUP_FW_CBASS_WKUP_0_CBASS_ERR_SLV_P2P_BRIDGE_IM4_WKUP_FW_CBASS_WKUP_0_CBASS_ERR_SLV_BRIDGE_BUSECC_ENABLE_CLR — Interrupt Enable Clear Register for m4_wkup_cbass_wkup_0_m4_wkup_cbass_Im4_wkup_fw_cbass_wkup_0_cbass_err_slv_p2p_bridge_Im4_wkup_fw_cbass_wkup_0_cbass_err_slv_bridge_busecc__pend (access RW1C)
  [9] M4_WKUP_CBASS_WKUP_0_M4_WKUP_CBASS_IM4_WKUP_CBASS_WKUP_0_CBASS_ERR_SLV_P2P_BRIDGE_IM4_WKUP_CBASS_WKUP_0_CBASS_ERR_SLV_BRIDGE_BUSECC_ENABLE_CLR — Interrupt Enable Clear Register for m4_wkup_cbass_wkup_0_m4_wkup_cbass_Im4_wkup_cbass_wkup_0_cbass_err_slv_p2p_bridge_Im4_wkup_cbass_wkup_0_cbass_err_slv_bridge_busecc__pend (access RW1C)
  [8] M4_WKUP_CBASS_WKUP_0_M4_WKUP_CBASS_IEXPORT_VBUSM_32B_SLV_WKUP_0_SLV_P2M_BRIDGE_IEXPORT_VBUSM_32B_SLV_WKUP_0_SLV_BRIDGE_SRC_BUSECC_ENABLE_CLR — Interrupt Enable Clear Register for m4_wkup_cbass_wkup_0_m4_wkup_cbass_Iexport_vbusm_32b_slv_wkup_0_slv_p2m_bridge_Iexport_vbusm_32b_slv_wkup_0_slv_bridge_src_busecc__pend (access RW1C)
  [7] M4_WKUP_CBASS_WKUP_0_M4_WKUP_CBASS_IEXPORT_VBUSM_32B_SLV_WKUP_0_SLV_P2M_BRIDGE_IEXPORT_VBUSM_32B_SLV_WKUP_0_SLV_BRIDGE_DST_BUSECC_ENABLE_CLR — Interrupt Enable Clear Register for m4_wkup_cbass_wkup_0_m4_wkup_cbass_Iexport_vbusm_32b_slv_wkup_0_slv_p2m_bridge_Iexport_vbusm_32b_slv_wkup_0_slv_bridge_dst_busecc__pend (access RW1C)
  [6] M4_WKUP_CBASS_WKUP_0_M4_WKUP_CBASS_IEXPORT_VBUSM_32B_MST_WKUP_0_MST_M2P_BRIDGE_IEXPORT_VBUSM_32B_MST_WKUP_0_MST_BRIDGE_SRC_BUSECC_ENABLE_CLR — Interrupt Enable Clear Register for m4_wkup_cbass_wkup_0_m4_wkup_cbass_Iexport_vbusm_32b_mst_wkup_0_mst_m2p_bridge_Iexport_vbusm_32b_mst_wkup_0_mst_bridge_src_busecc__pend (access RW1C)
  [5] M4_WKUP_CBASS_WKUP_0_M4_WKUP_CBASS_IEXPORT_VBUSM_32B_MST_WKUP_0_MST_M2P_BRIDGE_IEXPORT_VBUSM_32B_MST_WKUP_0_MST_BRIDGE_DST_BUSECC_ENABLE_CLR — Interrupt Enable Clear Register for m4_wkup_cbass_wkup_0_m4_wkup_cbass_Iexport_vbusm_32b_mst_wkup_0_mst_m2p_bridge_Iexport_vbusm_32b_mst_wkup_0_mst_bridge_dst_busecc__pend (access RW1C)
  [4] M4_WKUP_CBASS_WKUP_0_M4_WKUP_CBASS_SCRP_32B_PCLK4_WAKEUP_SCR_M4_WKUP_CBASS_SCRP_32B_PCLK4_WAKEUP_SCR_EDC_CTRL_BUSECC_1_ENABLE_CLR — Interrupt Enable Clear Register for m4_wkup_cbass_wkup_0_m4_wkup_cbass_SCRP_32b_PCLK4_wakeup_scr_m4_wkup_cbass_SCRP_32b_PCLK4_wakeup_scr_edc_ctrl_busecc_1__pend (access RW1C)
  [3] M4_WKUP_CBASS_WKUP_0_M4_WKUP_CBASS_SCRP_32B_PCLK4_WAKEUP_SCR_M4_WKUP_CBASS_SCRP_32B_PCLK4_WAKEUP_SCR_EDC_CTRL_BUSECC_0_ENABLE_CLR — Interrupt Enable Clear Register for m4_wkup_cbass_wkup_0_m4_wkup_cbass_SCRP_32b_PCLK4_wakeup_scr_m4_wkup_cbass_SCRP_32b_PCLK4_wakeup_scr_edc_ctrl_busecc_0__pend (access RW1C)
  [2] M4_WKUP_CBASS_WKUP_0_M4_WKUP_CBASS_CBASS_LPSC_WKUP_COMMON_ERR_M4_WKUP_CBASS_CBASS_LPSC_WKUP_COMMON_ERR_EDC_CTRL_BUSECC_ENABLE_CLR — Interrupt Enable Clear Register for m4_wkup_cbass_wkup_0_m4_wkup_cbass_cbass_LPSC_wkup_common_err_m4_wkup_cbass_cbass_LPSC_wkup_common_err_edc_ctrl_busecc__pend (access RW1C)
  [1] M4_WKUP_CBASS_WKUP_0_M4_WKUP_CBASS_BR_SCRP_32B_PCLK2_DMSC_TO_SCRP_32B_PCLK4_WAKEUP_L0_P2P_BRIDGE_BR_SCRP_32B_PCLK2_DMSC_TO_SCRP_32B_PCLK4_WAKEUP_L0_BRIDGE_SRC_BUSECC_ENABLE_CLR — Interrupt Enable Clear Register for m4_wkup_cbass_wkup_0_m4_wkup_cbass_br_SCRP_32b_PCLK2_DMSC_to_SCRP_32b_PCLK4_wakeup_l0_p2p_bridge_br_SCRP_32b_PCLK2_DMSC_to_SCRP_32b_PCLK4_wakeup_l0_bridge_src_busecc__pend (access RW1C)
  [0] M4_WKUP_CBASS_WKUP_0_M4_WKUP_CBASS_BR_SCRP_32B_PCLK2_DMSC_TO_SCRP_32B_PCLK4_WAKEUP_L0_P2P_BRIDGE_BR_SCRP_32B_PCLK2_DMSC_TO_SCRP_32B_PCLK4_WAKEUP_L0_BRIDGE_DST_BUSECC_ENABLE_CLR — Interrupt Enable Clear Register for m4_wkup_cbass_wkup_0_m4_wkup_cbass_br_SCRP_32b_PCLK2_DMSC_to_SCRP_32b_PCLK4_wakeup_l0_p2p_bridge_br_SCRP_32b_PCLK2_DMSC_to_SCRP_32b_PCLK4_wakeup_l0_bridge_dst_busecc__pend (access RW1C)
0xC4 CBASS_ECC_SEC_ENABLE_CLR_REG1 — Return to the . Interrupt Enable Clear Register 1
  [12] VDC_INFRA_VBUSP_32B_REF_WKUP2MAIN_INFRA_SRC_P2M_REASSEMBLY_BUSECC_ENABLE_CLR — Interrupt Enable Clear Register for vdc_infra_vbusp_32b_ref_wkup2main_infra_src_p2m_reassembly_busecc__pend (access RW1C)
  [11] VDC_INFRA_VBUSP_32B_REF_WKUP2MAIN_INFRA_M2M_SRC_VBUSS_ENABLE_CLR — Interrupt Enable Clear Register for vdc_infra_vbusp_32b_ref_wkup2main_infra_m2m_src_vbuss__pend (access RW1C)
  [10] VDC_INFRA_VBUSP_32B_REF_WKUP2MAIN_INFRA_SRC_P2M_DST_BUSECC_ENABLE_CLR — Interrupt Enable Clear Register for vdc_infra_vbusp_32b_ref_wkup2main_infra_src_p2m_dst_busecc__pend (access RW1C)
  [9] VDC_INFRA_VBUSP_32B_REF_WKUP2MAIN_INFRA_SRC_P2M_SRC_BUSECC_ENABLE_CLR — Interrupt Enable Clear Register for vdc_infra_vbusp_32b_ref_wkup2main_infra_src_p2m_src_busecc__pend (access RW1C)
  [8] VDC_SOC_FW_VBUSP_32B_REF_FWWKUP2MCU_SRC_P2M_REASSEMBLY_BUSECC_ENABLE_CLR — Interrupt Enable Clear Register for vdc_soc_fw_vbusp_32b_ref_fwwkup2mcu_src_p2m_reassembly_busecc__pend (access RW1C)
  [7] VDC_SOC_FW_VBUSP_32B_REF_FWWKUP2MCU_M2M_SRC_VBUSS_ENABLE_CLR — Interrupt Enable Clear Register for vdc_soc_fw_vbusp_32b_ref_fwwkup2mcu_m2m_src_vbuss__pend (access RW1C)
  [6] VDC_SOC_FW_VBUSP_32B_REF_FWWKUP2MCU_SRC_P2M_DST_BUSECC_ENABLE_CLR — Interrupt Enable Clear Register for vdc_soc_fw_vbusp_32b_ref_fwwkup2mcu_src_p2m_dst_busecc__pend (access RW1C)
  [5] VDC_SOC_FW_VBUSP_32B_REF_FWWKUP2MCU_SRC_P2M_SRC_BUSECC_ENABLE_CLR — Interrupt Enable Clear Register for vdc_soc_fw_vbusp_32b_ref_fwwkup2mcu_src_p2m_src_busecc__pend (access RW1C)
  [4] VDC_DATA_VBUSM_32B_REF_WKUP2MCU_SRC_VBUSS_ENABLE_CLR — Interrupt Enable Clear Register for vdc_data_vbusm_32b_ref_wkup2mcu_src_vbuss__pend (access RW1C)
  [3] VDC_DATA_VBUSM_32B_REF_MCU2WKUP_M2M_VBUSS_ENABLE_CLR — Interrupt Enable Clear Register for vdc_data_vbusm_32b_ref_mcu2wkup_m2m_vbuss__pend (access RW1C)
  [2] VDC_DATA_VBUSM_32B_REF_MCU2WKUP_DST_VBUSS_ENABLE_CLR — Interrupt Enable Clear Register for vdc_data_vbusm_32b_ref_mcu2wkup_dst_vbuss__pend (access RW1C)
  [1] M4_WKUP_FW_CBASS_WKUP_0_M4_WKUP_FW_CBASS_SCRP_WKUP_FW_CLK2_SCR_M4_WKUP_FW_CBASS_SCRP_WKUP_FW_CLK2_SCR_EDC_CTRL_BUSECC_ENABLE_CLR — Interrupt Enable Clear Register for m4_wkup_fw_cbass_wkup_0_m4_wkup_fw_cbass_SCRP_wkup_fw_CLK2_scr_m4_wkup_fw_cbass_SCRP_wkup_fw_CLK2_scr_edc_ctrl_busecc__pend (access RW1C)
  [0] M4_WKUP_FW_CBASS_WKUP_0_M4_WKUP_FW_CBASS_CBASS_LPSC_WKUP_COMMON_ERR_M4_WKUP_FW_CBASS_CBASS_LPSC_WKUP_COMMON_ERR_EDC_CTRL_BUSECC_ENABLE_CLR — Interrupt Enable Clear Register for m4_wkup_fw_cbass_wkup_0_m4_wkup_fw_cbass_cbass_LPSC_wkup_common_err_m4_wkup_fw_cbass_cbass_LPSC_wkup_common_err_edc_ctrl_busecc__pend (access RW1C)
0x13C CBASS_ECC_DED_EOI_REG — Return to the . EOI Register
  [0] EOI_WR — EOI Register (access RW1S)
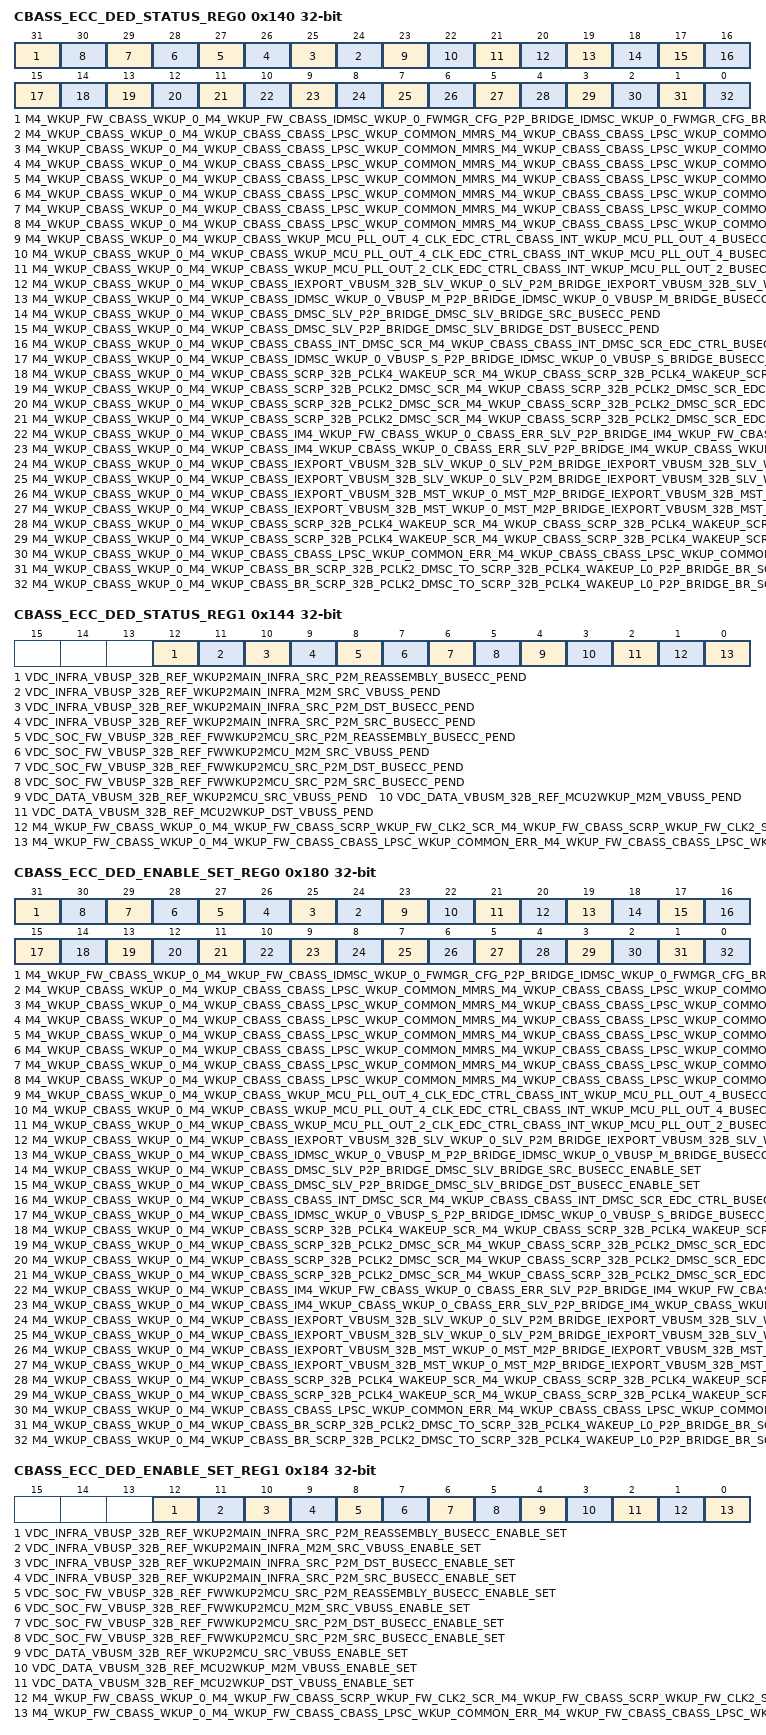
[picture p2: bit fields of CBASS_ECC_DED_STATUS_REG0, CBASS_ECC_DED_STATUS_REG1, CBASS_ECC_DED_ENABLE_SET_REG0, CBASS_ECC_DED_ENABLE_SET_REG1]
0x140 CBASS_ECC_DED_STATUS_REG0 — Return to the . Interrupt Status Register 0
  fields as CBASS_ECC_SEC_STATUS_REG0
0x144 CBASS_ECC_DED_STATUS_REG1 — Return to the . Interrupt Status Register 1
  fields as CBASS_ECC_SEC_STATUS_REG1
0x180 CBASS_ECC_DED_ENABLE_SET_REG0 — Return to the . Interrupt Enable Set Register 0
  fields as CBASS_ECC_SEC_ENABLE_SET_REG0
0x184 CBASS_ECC_DED_ENABLE_SET_REG1 — Return to the . Interrupt Enable Set Register 1
  fields as CBASS_ECC_SEC_ENABLE_SET_REG1
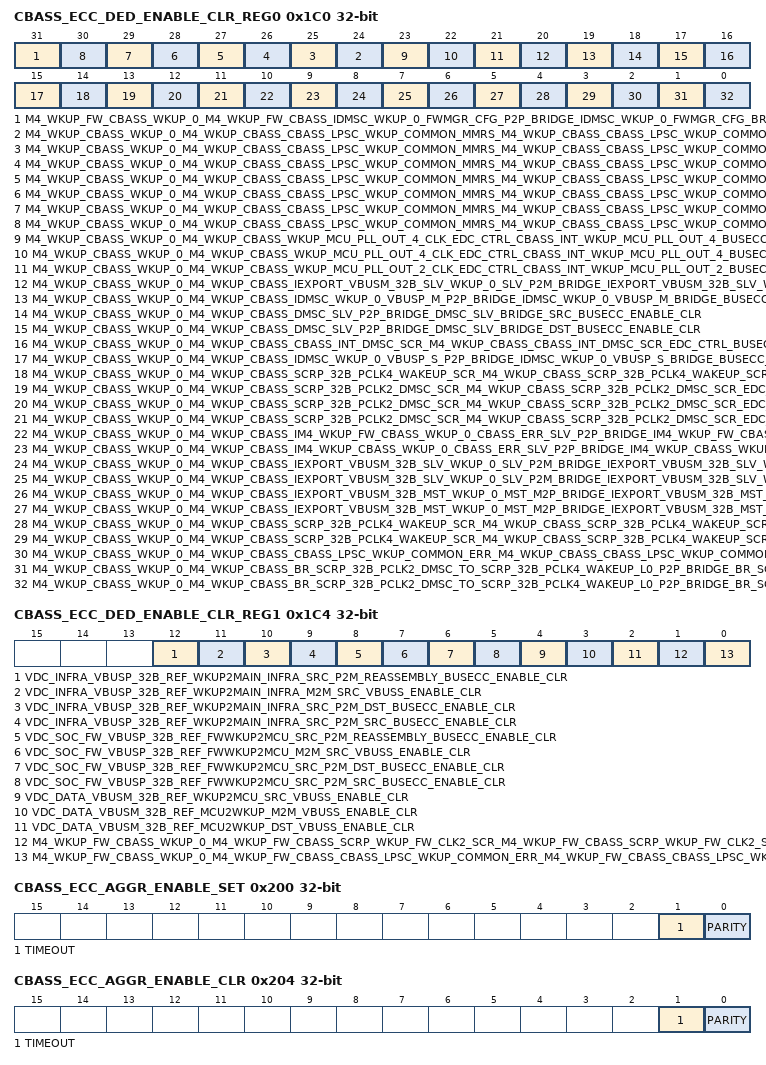
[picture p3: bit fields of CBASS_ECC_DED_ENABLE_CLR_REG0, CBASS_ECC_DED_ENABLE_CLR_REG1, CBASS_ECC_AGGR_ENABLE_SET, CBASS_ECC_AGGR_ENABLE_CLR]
0x1C0 CBASS_ECC_DED_ENABLE_CLR_REG0 — Return to the . Interrupt Enable Clear Register 0
  fields as CBASS_ECC_SEC_ENABLE_CLR_REG0
0x1C4 CBASS_ECC_DED_ENABLE_CLR_REG1 — Return to the . Interrupt Enable Clear Register 1
  fields as CBASS_ECC_SEC_ENABLE_CLR_REG1
0x200 CBASS_ECC_AGGR_ENABLE_SET — Return to the . AGGR interrupt enable set Register
  [1] TIMEOUT — interrupt enable set for svbus timeout errors (access RW1S)
  [0] PARITY — interrupt enable set for parity errors (access RW1S)
0x204 CBASS_ECC_AGGR_ENABLE_CLR — Return to the . AGGR interrupt enable clear Register
  [1] TIMEOUT — interrupt enable clear for svbus timeout errors (access RW1C)
  [0] PARITY — interrupt enable clear for parity errors (access RW1C)
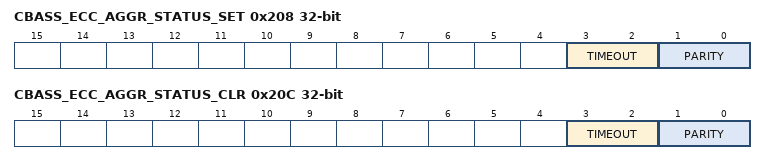
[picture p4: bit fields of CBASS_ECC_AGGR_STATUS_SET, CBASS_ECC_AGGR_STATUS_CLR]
0x208 CBASS_ECC_AGGR_STATUS_SET rw — Return to the . AGGR interrupt status set Register
  [3:2] TIMEOUT — interrupt status set for svbus timeout errors
  [1:0] PARITY — interrupt status set for parity errors
0x20C CBASS_ECC_AGGR_STATUS_CLR rw — Return to the . AGGR interrupt status clear Register
  [3:2] TIMEOUT — interrupt status clear for svbus timeout errors
  [1:0] PARITY — interrupt status clear for parity errors
